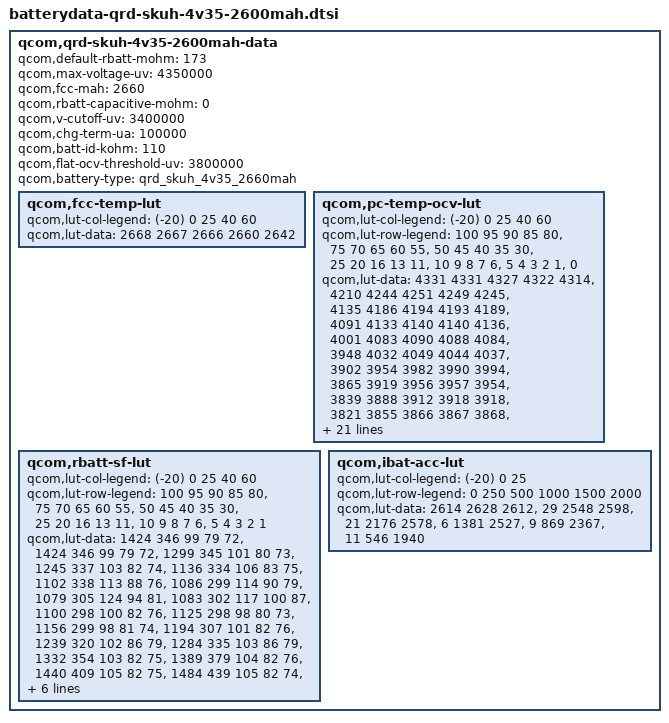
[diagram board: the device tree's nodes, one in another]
/* Copyright (c) 2014, The Linux Foundation. All rights reserved.
 *
 * This program is free software; you can redistribute it and/or modify
 * it under the terms of the GNU General Public License version 2 and
 * only version 2 as published by the Free Software Foundation.
 *
 * This program is distributed in the hope that it will be useful,
 * but WITHOUT ANY WARRANTY; without even the implied warranty of
 * MERCHANTABILITY or FITNESS FOR A PARTICULAR PURPOSE.  See the
 * GNU General Public License for more details.
 */

qcom,qrd-skuh-4v35-2600mah-data {
	qcom,default-rbatt-mohm = <173>;
	qcom,max-voltage-uv = <4350000>;
	qcom,fcc-mah = <2660>;
	qcom,rbatt-capacitive-mohm = <0>;
	qcom,v-cutoff-uv = <3400000>;
	qcom,chg-term-ua = <100000>;
	qcom,batt-id-kohm = <110>;
	qcom,flat-ocv-threshold-uv = <3800000>;
	qcom,battery-type = "qrd_skuh_4v35_2660mah";

	qcom,fcc-temp-lut {
		qcom,lut-col-legend = <(-20) 0 25 40 60>;
		qcom,lut-data = <2668 2667 2666 2660 2642>;
	};

	qcom,pc-temp-ocv-lut {
		qcom,lut-col-legend = <(-20) 0 25 40 60>;
		qcom,lut-row-legend = <100 95 90 85 80>,
				<75 70 65 60 55>,
				<50 45 40 35 30>,
				<25 20 16 13 11>,
				<10 9 8 7 6>,
				<5 4 3 2 1>,
				<0>;
		qcom,lut-data = <4331 4331 4327 4322 4314>,
				<4210 4244 4251 4249 4245>,
				<4135 4186 4194 4193 4189>,
				<4091 4133 4140 4140 4136>,
				<4001 4083 4090 4088 4084>,
				<3948 4032 4049 4044 4037>,
				<3902 3954 3982 3990 3994>,
				<3865 3919 3956 3957 3954>,
				<3839 3888 3912 3918 3918>,
				<3821 3855 3866 3867 3868>,
				<3805 3828 3837 3836 3837>,
				<3790 3804 3815 3816 3814>,
				<3776 3788 3797 3798 3796>,
				<3762 3776 3782 3783 3782>,
				<3746 3764 3769 3767 3763>,
				<3728 3749 3756 3749 3737>,
				<3708 3733 3740 3731 3717>,
				<3687 3720 3718 3710 3696>,
				<3668 3710 3698 3690 3677>,
				<3652 3702 3690 3682 3671>,
				<3644 3698 3689 3682 3670>,
				<3634 3693 3687 3680 3668>,
				<3620 3688 3686 3678 3667>,
				<3604 3680 3683 3676 3663>,
				<3584 3668 3676 3666 3652>,
				<3560 3647 3652 3640 3620>,
				<3528 3610 3606 3594 3574>,
				<3482 3556 3545 3534 3513>,
				<3410 3473 3462 3452 3430>,
				<3282 3338 3334 3321 3296>,
				<3000 3000 3018 3000 3000>;
	};
	
	qcom,rbatt-sf-lut {
		qcom,lut-col-legend = <(-20) 0 25 40 60>;
		qcom,lut-row-legend = <100 95 90 85 80>,
				<75 70 65 60 55>,
				<50 45 40 35 30>,
				<25 20 16 13 11>,
				<10 9 8 7 6>,
				<5 4 3 2 1>;
		qcom,lut-data = <1424 346 99 79 72>,
					<1424 346 99 79 72>,				
					<1299 345 101 80 73>,				
					<1245 337 103 82 74>,				
					<1136 334 106 83 75>,				
					<1102 338 113 88 76>,				
					<1086 299 114 90 79>,				
					<1079 305 124 94 81>,				
					<1083 302 117 100 87>,				
					<1100 298 100 82 76>,				
					<1125 298 98 80 73>,				
					<1156 299 98 81 74>,				
					<1194 307 101 82 76>,				
					<1239 320 102 86 79>,				
					<1284 335 103 86 79>,				
					<1332 354 103 82 75>,				
					<1389 379 104 82 76>,				
					<1440 409 105 82 75>,				
					<1484 439 105 82 74>,				
					<1512 453 105 82 75>,				
					<1477 443 105 84 76>,				
					<1545 455 107 86 77>,				
					<1660 472 110 87 81>,				
					<1798 488 115 90 83>,				
					<1971 509 118 92 83>,				
					<2207 527 116 88 78>,				
					<2523 550 114 87 79>,				
					<3032 591 119 90 82>,				
					<3940 654 128 97 87>,				
					<7881 1308 162 131 116>;
	};

	qcom,ibat-acc-lut {
		qcom,lut-col-legend = <(-20) 0 25>;
		qcom,lut-row-legend = <0 250 500 1000 1500 2000>;
		qcom,lut-data = <2614 2628 2612>,
				<29 2548 2598>,
				<21 2176 2578>,
				<6 1381 2527>,
				<9 869 2367>,				
				<11 546 1940>;
	};
};
